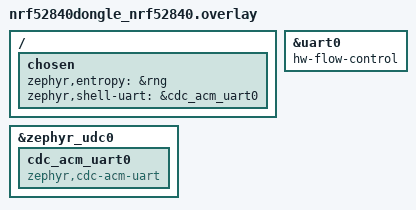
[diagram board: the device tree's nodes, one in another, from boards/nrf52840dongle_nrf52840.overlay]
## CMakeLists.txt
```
#
# Copyright (c) 2022, The OpenThread Authors.
# All rights reserved.
# BDS-3
#

cmake_minimum_required(VERSION 3.20.0)

find_package(Zephyr REQUIRED HINTS $ENV{ZEPHYR_BASE})

project(bbtc)

# NORDIC SDK APP START
target_sources(app PRIVATE src/main.c)
target_sources(app PRIVATE src/otPlatBle.c)
# NORDIC SDK APP END
```

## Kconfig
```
#
# Copyright (c) 2020 Nordic Semiconductor ASA
#
# SPDX-License-Identifier: LicenseRef-Nordic-5-Clause
#

menu "Zephyr Kernel"
source "Kconfig.zephyr"
endmenu

module = BBTC
module-str = bbtc
source "${ZEPHYR_BASE}/subsys/logging/Kconfig.template.log_config"
```

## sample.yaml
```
sample:
  name: BBTC
  description: Test BBTC build
tests:
  sample.openthread.bbtc:
    build_only: true
    platform_allow: nrf5340dk_nrf5340_cpuapp nrf52840dk_nrf52840 nrf52840dongle_nrf52840
    tags: build
    integration_platforms:
      - nrf5340dk_nrf5340_cpuapp
      - nrf52840dk_nrf52840
      - nrf52840dongle_nrf52840
```

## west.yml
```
# Copyright (c) 2023 Nordic Semiconductor ASA
# SPDX-License-Identifier: Apache-2.0

manifest:
  self:
    path: ThreadBleSecure-ncs

  remotes:
    - name: ncs
      url-base: https://github.com/nrfconnect
    - name: canis
      url-base: https://github.com/canisLupus1313

  projects:
    - name: openthread
      remote: canis
      revision: 442f2491efb3a973ef51b56cb48904f2e3eb05df
      path: modules/lib/openthread
    - name: sdk-nrf
      remote: ncs
      revision: v2.3.0
      path: nrf
      import:
        name-blocklist:
          - openthread
          - zephyr
    - name: zephyr
      repo-path: sdk-zephyr
      revision: 9a30ca95bdf405045992ebebe20b5765492bda53
      remote: canis
      import:
        # In addition to the zephyr repository itself, NCS also
        # imports the contents of zephyr/west.yml at the above
        # revision. Only the projects explicitly named in the
        # following allowlist are imported.
        #
        # Note that the zephyr west extensions (like 'build', 'flash',
        # 'debug', etc.) are automatically provided by this import, so
        # there's no need to add a redundant west-commands: key for
        # the zephyr project.
        #
        # Please keep this list sorted alphabetically.
        name-allowlist:
          - TraceRecorderSource
          - canopennode
          - chre
          - cmsis
          - edtt
          - fatfs
          - hal_nordic
          - hal_st # required for ST sensors (unrelated to STM32 MCUs)
          - hal_wurthelektronik
          - liblc3
          - libmetal
          - littlefs
          - loramac-node
          - lvgl
          - lz4
          - mipi-sys-t
          - nanopb
          - net-tools
          - nrf_hw_models
          - open-amp
          - picolibc
          - psa-arch-tests
          - segger
          - tinycbor
          - tinycrypt
          - tf-m-tests
          - uoscore-uedhoc
          - zcbor
          - zscilib
```

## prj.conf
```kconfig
# Copyright (c) 2021 Nordic Semiconductor ASA
# SPDX-License-Identifier: Apache-2.0

# Network shell
CONFIG_SHELL=y
CONFIG_OPENTHREAD_SHELL=y
CONFIG_SHELL_ARGC_MAX=26
CONFIG_SHELL_CMD_BUFF_SIZE=640

# Enable OpenThread features set
CONFIG_OPENTHREAD_NORDIC_LIBRARY_MASTER=y

CONFIG_NET_L2_OPENTHREAD=y

# Enable Ble feture set
CONFIG_OPENTHREAD_BBTC=y
CONFIG_MBEDTLS_GCM_C=y
# Increase MbedTLS heap size from 900 to 2000 for both input and output. Add 2x 1100 to the default value of 10240
CONFIG_MBEDTLS_HEAP_SIZE=12440
CONFIG_MBEDTLS_KEY_EXCHANGE_PSK_ENABLED=y


# Generic networking options
CONFIG_NETWORKING=y

CONFIG_ASSERT=y
CONFIG_ASSERT_NO_COND_INFO=y
CONFIG_MBEDTLS_SHA1_C=n
CONFIG_FPU=y

# Multiprotocol
# -------------
CONFIG_SYSTEM_WORKQUEUE_STACK_SIZE=2144
CONFIG_BT_RX_STACK_SIZE=2048

CONFIG_BT=y
CONFIG_BT_PERIPHERAL=y
CONFIG_BT_DEVICE_NAME="Thread BLE"
CONFIG_BT_DEVICE_APPEARANCE=833

# OpenThread default network config
CONFIG_OPENTHREAD_NETWORKKEY="00:11:22:33:44:55:66:77:88:99:aa:bb:cc:dd:ee:ff"
CONFIG_OPENTHREAD_NETWORK_NAME="OpenThread-7cf7"
CONFIG_OPENTHREAD_XPANID="3b:78:ce:62:9c:bc:8e:23"
CONFIG_OPENTHREAD_PANID=31991
```

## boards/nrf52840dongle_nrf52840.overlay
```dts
/* Copyright (c) 2023 Nordic Semiconductor ASA
 *
 * SPDX-License-Identifier: LicenseRef-Nordic-5-Clause
 */

&uart0 {
	status = "okay";
	hw-flow-control;
};

&zephyr_udc0 {
	cdc_acm_uart0: cdc_acm_uart0 {
		compatible = "zephyr,cdc-acm-uart";
	};
};

/ {
	/*
	* In some default configurations within the nRF Connect SDK,
	* e.g. on nRF52840, the chosen zephyr,entropy node is &cryptocell.
	* This devicetree overlay ensures that default is overridden wherever it
	* is set, as this application uses the RNG node for entropy exclusively.
	*/
	chosen {
		zephyr,entropy = &rng;
		zephyr,shell-uart = &cdc_acm_uart0;
	};
};
```

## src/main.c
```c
/*
 *  Copyright (c) 2022, The OpenThread Authors.
 *  All rights reserved.
 *
 *  Redistribution and use in source and binary forms, with or without
 *  modification, are permitted provided that the following conditions are met:
 *  1. Redistributions of source code must retain the above copyright
 *     notice, this list of conditions and the following disclaimer.
 *  2. Redistributions in binary form must reproduce the above copyright
 *     notice, this list of conditions and the following disclaimer in the
 *     documentation and/or other materials provided with the distribution.
 *  3. Neither the name of the copyright holder nor the
 *     names of its contributors may be used to endorse or promote products
 *     derived from this software without specific prior written permission.
 *
 *  THIS SOFTWARE IS PROVIDED BY THE COPYRIGHT HOLDERS AND CONTRIBUTORS "AS IS"
 *  AND ANY EXPRESS OR IMPLIED WARRANTIES, INCLUDING, BUT NOT LIMITED TO, THE
 *  IMPLIED WARRANTIES OF MERCHANTABILITY AND FITNESS FOR A PARTICULAR PURPOSE
 *  ARE DISCLAIMED. IN NO EVENT SHALL THE COPYRIGHT HOLDER OR CONTRIBUTORS BE
 *  LIABLE FOR ANY DIRECT, INDIRECT, INCIDENTAL, SPECIAL, EXEMPLARY, OR
 *  CONSEQUENTIAL DAMAGES (INCLUDING, BUT NOT LIMITED TO, PROCUREMENT OF
 *  SUBSTITUTE GOODS OR SERVICES; LOSS OF USE, DATA, OR PROFITS; OR BUSINESS
 *  INTERRUPTION) HOWEVER CAUSED AND ON ANY THEORY OF LIABILITY, WHETHER IN
 *  CONTRACT, STRICT LIABILITY, OR TORT (INCLUDING NEGLIGENCE OR OTHERWISE)
 *  ARISING IN ANY WAY OUT OF THE USE OF THIS SOFTWARE, EVEN IF ADVISED OF THE
 *  POSSIBILITY OF SUCH DAMAGE.
 */

#include <zephyr/kernel.h>
#include <zephyr/logging/log.h>

#include <zephyr/drivers/uart.h>
#include <zephyr/usb/usb_device.h>

// Zephyr OpenThread integration Library
#include <zephyr/net/openthread.h>

// OpenThread API
#include <openthread/platform/ble.h>
#include <openthread/ble_secure.h>

#include "x509_cert_key.h"


LOG_MODULE_REGISTER(cli_sample, CONFIG_OT_COMMAND_LINE_INTERFACE_LOG_LEVEL);

struct openthread_context *myOpenThreadContext;
otInstance *myOpenThreadInstance = NULL;  


// BleSecure callback functions

void HandleBleSecureClientConnect(bool aConnected, void *aContext)
{
	LOG_INF("TLS Connected: %s", aConnected ? "YES" : " NO");
}


void HandleBleSecureReceive(otMessage *aMessage, void *aContext)
{
	uint16_t nLen;
	char buf[100];
	
	LOG_INF("TLS Data Received len:%d offset:%d", (int)otMessageGetLength(aMessage), (int)otMessageGetOffset(aMessage));

	//nLen = otMessageGetLength(aMessage) - otMessageGetOffset(aMessage);
    nLen = otMessageRead(aMessage, otMessageGetOffset(aMessage), buf + 5, sizeof(buf) - 6);
	buf[nLen + 5] = 0;

	LOG_INF("Received:%s", buf + 5);
	memcpy(buf, "RECV:", 5);
	otBleSecureSend(myOpenThreadInstance, buf, strlen(buf));
}


// platform -> integrate in OT
void otPlatBleGapOnConnected(otInstance *aInstance, uint16_t aConnectionId)
{
	LOG_INF("OT Connected");
	otBleSecureConnect(myOpenThreadInstance, HandleBleSecureClientConnect, NULL);
}

void otPlatBleGapOnDisconnected(otInstance *aInstance, uint16_t aConnectionId)
{
	LOG_INF("OT Disconnected");
	otBleSecureDisconnect(myOpenThreadInstance);
}


void main(void)
{
#if DT_NODE_HAS_COMPAT(DT_CHOSEN(zephyr_shell_uart), zephyr_cdc_acm_uart)
	int ret;
	const struct device *dev;
	uint32_t dtr = 0U;

	ret = usb_enable(NULL);
	if (ret != 0) {
		LOG_ERR("Failed to enable USB");
		return;
	}

	dev = DEVICE_DT_GET(DT_CHOSEN(zephyr_shell_uart));
	if (dev == NULL) {
		LOG_ERR("Failed to find specific UART device");
		return;
	}

	LOG_INF("Waiting for host to be ready to communicate");

	/* Data Terminal Ready - check if host is ready to communicate */
	while (!dtr) {
		ret = uart_line_ctrl_get(dev, UART_LINE_CTRL_DTR, &dtr);
		if (ret) {
			LOG_ERR("Failed to get Data Terminal Ready line state: %d",
				ret);
			continue;
		}
		k_msleep(100);
	}

	/* Data Carrier Detect Modem - mark connection as established */
	(void)uart_line_ctrl_set(dev, UART_LINE_CTRL_DCD, 1);
	/* Data Set Ready - the NCP SoC is ready to communicate */
	(void)uart_line_ctrl_set(dev, UART_LINE_CTRL_DSR, 1);
#endif

	myOpenThreadContext = openthread_get_default_context();
	myOpenThreadInstance = myOpenThreadContext->instance;

	#if CONFIG_BT
		otBleSecureSetCertificate(myOpenThreadInstance, (const uint8_t*)(OT_CLI_COAPS_X509_CERT),
                               sizeof(OT_CLI_COAPS_X509_CERT), (const uint8_t*)(OT_CLI_COAPS_PRIV_KEY),
                               sizeof(OT_CLI_COAPS_PRIV_KEY));

    	otBleSecureSetCaCertificateChain(myOpenThreadInstance,
                                      (const uint8_t*)(OT_CLI_COAPS_TRUSTED_ROOT_CERTIFICATE),
                                      sizeof(OT_CLI_COAPS_TRUSTED_ROOT_CERTIFICATE));

		otBleSecureSetSslAuthMode(myOpenThreadInstance, true);

		//otBleSecureSetPsk(myOpenThreadInstance, "SECRET", 6, "MyDevice", 8);
		otBleSecureStart(myOpenThreadInstance, HandleBleSecureReceive, false, NULL);
			
	#endif
}
```

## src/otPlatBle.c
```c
/*
 *  Copyright (c) 2022, The OpenThread Authors.
 *  All rights reserved.
 *
 *  Redistribution and use in source and binary forms, with or without
 *  modification, are permitted provided that the following conditions are met:
 *  1. Redistributions of source code must retain the above copyright
 *     notice, this list of conditions and the following disclaimer.
 *  2. Redistributions in binary form must reproduce the above copyright
 *     notice, this list of conditions and the following disclaimer in the
 *     documentation and/or other materials provided with the distribution.
 *  3. Neither the name of the copyright holder nor the
 *     names of its contributors may be used to endorse or promote products
 *     derived from this software without specific prior written permission.
 *
 *  THIS SOFTWARE IS PROVIDED BY THE COPYRIGHT HOLDERS AND CONTRIBUTORS "AS IS"
 *  AND ANY EXPRESS OR IMPLIED WARRANTIES, INCLUDING, BUT NOT LIMITED TO, THE
 *  IMPLIED WARRANTIES OF MERCHANTABILITY AND FITNESS FOR A PARTICULAR PURPOSE
 *  ARE DISCLAIMED. IN NO EVENT SHALL THE COPYRIGHT HOLDER OR CONTRIBUTORS BE
 *  LIABLE FOR ANY DIRECT, INDIRECT, INCIDENTAL, SPECIAL, EXEMPLARY, OR
 *  CONSEQUENTIAL DAMAGES (INCLUDING, BUT NOT LIMITED TO, PROCUREMENT OF
 *  SUBSTITUTE GOODS OR SERVICES; LOSS OF USE, DATA, OR PROFITS; OR BUSINESS
 *  INTERRUPTION) HOWEVER CAUSED AND ON ANY THEORY OF LIABILITY, WHETHER IN
 *  CONTRACT, STRICT LIABILITY, OR TORT (INCLUDING NEGLIGENCE OR OTHERWISE)
 *  ARISING IN ANY WAY OUT OF THE USE OF THIS SOFTWARE, EVEN IF ADVISED OF THE
 *  POSSIBILITY OF SUCH DAMAGE.
 */


// C standard libraries
#include <stddef.h>
#include <string.h>
#include <errno.h>


// Zephir Libraries
#include <zephyr/kernel.h>
#include <zephyr/logging/log.h>
#include <zephyr/types.h>
#include <zephyr/sys/byteorder.h>
#include <soc.h>
#include <zephyr/sys/ring_buffer.h>

#include <zephyr/bluetooth/bluetooth.h>
#include <zephyr/bluetooth/hci.h>
#include <zephyr/bluetooth/conn.h>
#include <zephyr/bluetooth/uuid.h>
#include <zephyr/bluetooth/gatt.h>

// Zephyr OpenThread integration Library
#include <zephyr/net/openthread.h>

// OpenThread BLE driver API
#include <openthread/platform/ble.h>


// --------------
// Zephyr Logging
// --------------

LOG_MODULE_REGISTER(cli_sample_ble_driver, CONFIG_OT_COMMAND_LINE_INTERFACE_LOG_LEVEL);



// ----------------
// Settings
// ----------------

#define DEVICE_NAME 		    CONFIG_BT_DEVICE_NAME
#define DEVICE_NAME_LEN        	(sizeof(DEVICE_NAME) - 1)

// Temporarily use the UUIDs of the Nordic UART service to allow using existing tools for testing
// This will be replaced with a Threadgroup UUID
#define MY_SERVICE_UUID 		BT_UUID_128_ENCODE(0x6e400001, 0xb5a3, 0xf393, 0xe0a9, 0xe50e24dcca9e)
#define RX_CHARACTERISTIC_UUID 	BT_UUID_128_ENCODE(0x6e400002, 0xb5a3, 0xf393, 0xe0a9, 0xe50e24dcca9e)
#define TX_CHARACTERISTIC_UUID  BT_UUID_128_ENCODE(0x6e400003, 0xb5a3, 0xf393, 0xe0a9, 0xe50e24dcca9e)


#define BT_UUID_MY_SERVICE      BT_UUID_DECLARE_128(MY_SERVICE_UUID)
#define BT_UUID_MY_SERVICE_RX   BT_UUID_DECLARE_128(RX_CHARACTERISTIC_UUID)
#define BT_UUID_MY_SERVICE_TX   BT_UUID_DECLARE_128(TX_CHARACTERISTIC_UUID)

#define PLAT_BLE_RING_BUF_SIZE  	500
#define PLAT_BLE_THREAD_STACK_SIZE  6500
#define PLAT_BLE_THREAD_DEALY  		500
#define PLAT_BLE_MSG_DATA_MAX  		23                  // must match the maximum MTU size used

#define PLAT_BLE_MSG_CONNECT  		0xFE
#define PLAT_BLE_MSG_DISCONNECT		0xFF


// ---------------------------------
// Zephyr Kernel Objects
// ---------------------------------

static void otPlatBleThread(void *, void *, void *);
uint8_t otPlatBleMsgBuf[PLAT_BLE_MSG_DATA_MAX];

K_SEM_DEFINE(otPlatBleInitSemaphor, 0, 1);
K_SEM_DEFINE(otPlatBleEventSemaphor, 0, 10000);
RING_BUF_DECLARE(otPlatBleRingBuf, PLAT_BLE_RING_BUF_SIZE);
K_THREAD_DEFINE(otPlatBleTid, PLAT_BLE_THREAD_STACK_SIZE, otPlatBleThread, NULL, NULL, NULL, 5, 0, PLAT_BLE_THREAD_DEALY);


// ---------------------------------
// OpenThread Objects
// ---------------------------------

otInstance *otPlatBleOpenThreadInstance = NULL;


// ---------------------------------
// BLE service Objects
// ---------------------------------

// forward declaration for callback functions
static ssize_t on_receive(struct bt_conn *conn, const struct bt_gatt_attr *attr, const void *buf,  uint16_t len,  uint16_t offset,  uint8_t flags);
void on_cccd_changed(const struct bt_gatt_attr *attr, uint16_t value);

// Service Declaration and Registration
BT_GATT_SERVICE_DEFINE(my_service,
    BT_GATT_PRIMARY_SERVICE(BT_UUID_MY_SERVICE),
    BT_GATT_CHARACTERISTIC(BT_UUID_MY_SERVICE_RX, BT_GATT_CHRC_WRITE | BT_GATT_CHRC_WRITE_WITHOUT_RESP, BT_GATT_PERM_READ | BT_GATT_PERM_WRITE, NULL, on_receive, NULL),
    BT_GATT_CHARACTERISTIC(BT_UUID_MY_SERVICE_TX, BT_GATT_CHRC_NOTIFY, BT_GATT_PERM_READ, NULL, NULL, NULL),
    BT_GATT_CCC(on_cccd_changed, BT_GATT_PERM_READ | BT_GATT_PERM_WRITE),
);



// ---------------------------------
// Zephyr BLE Objects
// ---------------------------------

// forward declaration for callback functions
static void connected(struct bt_conn *conn, uint8_t err);
static void disconnected(struct bt_conn *conn, uint8_t reason);
static bool le_param_req(struct bt_conn *conn, struct bt_le_conn_param *param);
static void le_param_updated(struct bt_conn *conn, uint16_t interval, uint16_t latency, uint16_t timeout);

static struct bt_conn *otPlatBleConnection = NULL;

static struct bt_conn_cb conn_callbacks = {
	.connected		    = connected,
	.disconnected   	= disconnected,
	.le_param_req		= le_param_req,
	.le_param_updated	= le_param_updated
};

static const struct bt_data ad[] =
{
	BT_DATA_BYTES(BT_DATA_FLAGS, (BT_LE_AD_GENERAL | BT_LE_AD_NO_BREDR)), BT_DATA(BT_DATA_NAME_COMPLETE, DEVICE_NAME, DEVICE_NAME_LEN),
};

static const struct bt_data sd[] =
{
	BT_DATA_BYTES(BT_DATA_UUID128_ALL, MY_SERVICE_UUID),
};



// ------------------------------------------------------------------
// Zephyr BLE Message Queue and Thread
// ------------------------------------------------------------------

// SDK integration: Should be includeded in the OpenThread Thread to avoid the need for another Thread with large stack

static bool otPlatBleQueueMsg(const uint8_t* aData, uint8_t aLen, int8_t aRssi)
{
	bool bRetVal;

	if(aLen <= PLAT_BLE_MSG_DATA_MAX && aData == NULL) return false;

	k_sched_lock();

	if(ring_buf_space_get(&otPlatBleRingBuf) >= sizeof(aLen) + sizeof(aRssi) + (aLen <= PLAT_BLE_MSG_DATA_MAX) ? aLen : 0)
    {
		ring_buf_put(&otPlatBleRingBuf, &aLen, sizeof(aLen));
		ring_buf_put(&otPlatBleRingBuf, &aRssi, sizeof(aRssi));
		if(aLen <= PLAT_BLE_MSG_DATA_MAX) ring_buf_put(&otPlatBleRingBuf, aData, aLen);
		k_sem_give(&otPlatBleEventSemaphor);
		bRetVal = true;
	}
	else bRetVal = false;

	k_sched_unlock();

	return bRetVal;
}


static void otPlatBleThread(void *a, void *b, void *c)
{
	OT_UNUSED_VARIABLE(a);
	OT_UNUSED_VARIABLE(b);
	OT_UNUSED_VARIABLE(c);

	uint8_t len;
	int8_t rssi;
	otBleRadioPacket myPacket;

	LOG_INF("otPlatBleThread started");

	while(1)
    {
        k_sem_take(&otPlatBleEventSemaphor, K_FOREVER);
        ring_buf_get(&otPlatBleRingBuf, &len, sizeof(len));
		ring_buf_get(&otPlatBleRingBuf, &rssi, sizeof(rssi));
        if(len <= PLAT_BLE_MSG_DATA_MAX) ring_buf_get(&otPlatBleRingBuf, otPlatBleMsgBuf, len);

		openthread_api_mutex_lock(openthread_get_default_context());

		if(len <= PLAT_BLE_MSG_DATA_MAX)
		{
			// The packet parameter in otPlatBleGattServerOnWriteRequest is not const. Re-write all members.
			myPacket.mValue = otPlatBleMsgBuf;
			myPacket.mPower = rssi;
			myPacket.mLength = len;
			otPlatBleGattServerOnWriteRequest(otPlatBleOpenThreadInstance, 0, &myPacket);
		}
		else if(len == PLAT_BLE_MSG_CONNECT) otPlatBleGapOnConnected(otPlatBleOpenThreadInstance, 0);
		else if(len == PLAT_BLE_MSG_DISCONNECT) otPlatBleGapOnDisconnected(otPlatBleOpenThreadInstance, 0);

		openthread_api_mutex_unlock(openthread_get_default_context());
	}
}


// ------------------------------------------------------------------
// Zephyr BLE service callbacks
// ------------------------------------------------------------------

/* This function is called whenever the RX Characteristic has been written to by a Client */
static ssize_t on_receive(struct bt_conn *conn, const struct bt_gatt_attr *attr, const void *buf,  uint16_t len,  uint16_t offset,  uint8_t flags)
{
	LOG_INF("Received data, handle %d, len %d", attr->handle, len);

	otPlatBleQueueMsg(buf, len, 0 /* TBD */);

	return len;
}


/* This function is called whenever a Notification has been sent by the TX Characteristic */
static void on_sent(struct bt_conn *conn, void *user_data)
{
	ARG_UNUSED(user_data);

	// LOG_INF("Data sent\n");
}


/* This function is called whenever the CCCD register has been changed by the client*/
void on_cccd_changed(const struct bt_gatt_attr *attr, uint16_t value)
{
    ARG_UNUSED(attr);
    switch(value)
    {
        case BT_GATT_CCC_NOTIFY:
			// How should the device driver inform about CCCD change?
			// Quick fix: Delay otPlatBleGapOnConnected(...) until notifications can be sent.
		    otPlatBleQueueMsg(NULL, PLAT_BLE_MSG_CONNECT, 0);
            break;

        case BT_GATT_CCC_INDICATE:
            break;

        case 0:
            break;
    }
}


otError otPlatBleGattServerIndicate(otInstance *aInstance, uint16_t aHandle, otBleRadioPacket *aPacket)
{
	OT_UNUSED_VARIABLE(aInstance);

    const struct bt_gatt_attr *attr = &my_service.attrs[3];

    struct bt_gatt_notify_params params =
    {
        .uuid   = BT_UUID_MY_SERVICE_TX,
        .attr   = attr,
        .data   = aPacket->mValue,
        .len    = aPacket->mLength,
        .func   = on_sent
    };

	// Only one connection supported
	if(aHandle != 0) return OT_ERROR_INVALID_ARGS;

	if(otPlatBleConnection == NULL) return OT_ERROR_INVALID_STATE;

    // Check whether notifications are enabled or not
    if(bt_gatt_is_subscribed(otPlatBleConnection, attr, BT_GATT_CCC_NOTIFY))
    {
        // Send the notification
	    if(bt_gatt_notify_cb(otPlatBleConnection, &params))
        {
            LOG_INF("Error, unable to send notification\n");
			return OT_ERROR_INVALID_ARGS;
        }
    }
    else
    {
        LOG_INF("Warning, notification not enabled on the selected attribute\n");
		return OT_ERROR_INVALID_STATE;
    }

	return OT_ERROR_NONE;
}


otError otPlatBleGattMtuGet(otInstance *aInstance, uint16_t *aMtu)
{
	OT_UNUSED_VARIABLE(aInstance);

	if(otPlatBleConnection == NULL) return OT_ERROR_FAILED;

	if(aMtu != NULL) *aMtu = bt_gatt_get_mtu(otPlatBleConnection);

	return OT_ERROR_NONE;
}


otError otPlatBleGapDisconnect(otInstance *aInstance)
{
	OT_UNUSED_VARIABLE(aInstance);

	if(otPlatBleConnection == NULL) return OT_ERROR_INVALID_STATE;

	if(bt_conn_disconnect(otPlatBleConnection, BT_HCI_ERR_REMOTE_USER_TERM_CONN))
	{
		return OT_ERROR_INVALID_STATE;
	}

	return OT_ERROR_NONE;
}

// ------------------------------------------------------------------
// Zephyr BLE callbacks
// ------------------------------------------------------------------

static void connected(struct bt_conn *conn, uint8_t err)
{
	struct bt_conn_info info;
	char addr[BT_ADDR_LE_STR_LEN];

	otPlatBleConnection = bt_conn_ref(conn);

	if(err)
	{
		LOG_INF("Connection failed (err %u)\n", err);
		return;
	}
	else if(bt_conn_get_info(conn, &info))
	{
		LOG_INF("Could not parse connection info\n");
	}
	else
	{
		bt_addr_le_to_str(bt_conn_get_dst(conn), addr, sizeof(addr));

		LOG_INF("Connection established!\n");
	}
}


static void disconnected(struct bt_conn *conn, uint8_t reason)
{
	LOG_INF("Disconnected (reason %u)\n", reason);

	if(otPlatBleConnection)
	{
		bt_conn_unref(otPlatBleConnection);
		otPlatBleConnection = NULL;

		otPlatBleQueueMsg(NULL, PLAT_BLE_MSG_DISCONNECT, 0);
	}
}


static bool le_param_req(struct bt_conn *conn, struct bt_le_conn_param *param)
{
	return true;
}


static void le_param_updated(struct bt_conn *conn, uint16_t interval, uint16_t latency, uint16_t timeout)
{
	struct bt_conn_info info;
	char addr[BT_ADDR_LE_STR_LEN];

	if(bt_conn_get_info(conn, &info))
	{
		LOG_INF("Could not parse connection info\n");
	}
	else
	{
		bt_addr_le_to_str(bt_conn_get_dst(conn), addr, sizeof(addr));

		LOG_INF("Connection parameters updated!\n");
	}
}


static void bt_ready(int err)
{
	if(err)
    {
		LOG_INF("BLE init failed with error code %d\n", err);
		return;
	}

	bt_conn_cb_register(&conn_callbacks);

    k_sem_give(&otPlatBleInitSemaphor);   // BLE stack up an running
}


otError otPlatBleGapAdvStart(otInstance *aInstance, uint16_t aInterval, uint8_t aType)
{
	OT_UNUSED_VARIABLE(aInstance);
	OT_UNUSED_VARIABLE(aInterval);			// To be decided how to derive the min max range from this value
	OT_UNUSED_VARIABLE(aType);				// Not need. Must be connectable for BLE secure.

	int err;

	err = bt_le_adv_start(BT_LE_ADV_CONN, ad, ARRAY_SIZE(ad), sd, ARRAY_SIZE(sd));

	if(err)
	{
		LOG_INF("Advertising failed to start (err %d)\n", err);
		return OT_ERROR_INVALID_STATE;
	}

	LOG_INF("Advertising successfully started\n");

	return OT_ERROR_NONE;
}


otError otPlatBleGapAdvStop(otInstance *aInstance)
{
	OT_UNUSED_VARIABLE(aInstance);

	bt_le_adv_stop();

	return OT_ERROR_NONE;
}



// ------------------------------------------------------------------
// Zephyr BLE initialization
// ------------------------------------------------------------------

otError otPlatBleEnable(otInstance *aInstance)
{
    int err;

	otPlatBleOpenThreadInstance = aInstance;
    err = bt_enable(bt_ready);

    if(err)
    {
		LOG_INF("BLE enable failed with error code %d\n", err);
		return OT_ERROR_FAILED;
	}

    err = k_sem_take(&otPlatBleInitSemaphor, K_MSEC(500));

	if (!err)
	{
		LOG_INF("Bluetooth initialized\n");
	}
	else
	{
		LOG_INF("BLE initialization did not complete in time\n");
		return OT_ERROR_FAILED;
	}

	return OT_ERROR_NONE;
}

otError otPlatBleDisable(otInstance *aInstance)
{
	OT_UNUSED_VARIABLE(aInstance);

	bt_disable();

	return OT_ERROR_NONE;
}
```

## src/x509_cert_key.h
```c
/*
 *  Copyright (c) 2022, The OpenThread Authors.
 *  All rights reserved.
 *
 *  Redistribution and use in source and binary forms, with or without
 *  modification, are permitted provided that the following conditions are met:
 *  1. Redistributions of source code must retain the above copyright
 *     notice, this list of conditions and the following disclaimer.
 *  2. Redistributions in binary form must reproduce the above copyright
 *     notice, this list of conditions and the following disclaimer in the
 *     documentation and/or other materials provided with the distribution.
 *  3. Neither the name of the copyright holder nor the
 *     names of its contributors may be used to endorse or promote products
 *     derived from this software without specific prior written permission.
 *
 *  THIS SOFTWARE IS PROVIDED BY THE COPYRIGHT HOLDERS AND CONTRIBUTORS "AS IS"
 *  AND ANY EXPRESS OR IMPLIED WARRANTIES, INCLUDING, BUT NOT LIMITED TO, THE
 *  IMPLIED WARRANTIES OF MERCHANTABILITY AND FITNESS FOR A PARTICULAR PURPOSE
 *  ARE DISCLAIMED. IN NO EVENT SHALL THE COPYRIGHT HOLDER OR CONTRIBUTORS BE
 *  LIABLE FOR ANY DIRECT, INDIRECT, INCIDENTAL, SPECIAL, EXEMPLARY, OR
 *  CONSEQUENTIAL DAMAGES (INCLUDING, BUT NOT LIMITED TO, PROCUREMENT OF
 *  SUBSTITUTE GOODS OR SERVICES; LOSS OF USE, DATA, OR PROFITS; OR BUSINESS
 *  INTERRUPTION) HOWEVER CAUSED AND ON ANY THEORY OF LIABILITY, WHETHER IN
 *  CONTRACT, STRICT LIABILITY, OR TORT (INCLUDING NEGLIGENCE OR OTHERWISE)
 *  ARISING IN ANY WAY OUT OF THE USE OF THIS SOFTWARE, EVEN IF ADVISED OF THE
 *  POSSIBILITY OF SUCH DAMAGE.
 */

/**
 * @file
 * @brief
 *  This file contains the X.509 certificate and private key for Application
 *  CoAP Secure use with cipher suite ECDHE_ECDSA_WITH_AES_128_CCM8.
 */


/**SERVER
 * Generate your own private key and certificate using openssl.
 *
 * 1. Generate a EC (Elliptic Curve) Private Key.
 *      'openssl ecparam -genkey -out myECKey.pem -name prime256v1 -noout'
 * 2. Generate a .X509 Certificate (Contains Public Key).
 *      'openssl req -x509 -new -key myECKey.pem -out myX509Cert.pem'
 */

/**
 * place your X.509 certificate (PEM format) for ssl session
 * with ECDHE_ECDSA_WITH_AES_128_CCM_8 here.
 */
#define OT_CLI_COAPS_X509_CERT                                             \
    "-----BEGIN CERTIFICATE-----\r\n"                                      \
    "MIIBrTCCAVICBgDRArfDJTAKBggqhkjOPQQDAjBcMQswCQYDVQQGEwJaWTESMBAG\r\n" \
    "A1UECAwJWW91clN0YXRlMRAwDgYDVQQKDAdZb3VyT3JnMRQwEgYDVQQLDAtZb3Vy\r\n" \
    "T3JnVW5pdDERMA8GA1UEAwwIVmVuZG9yQ0EwIBcNMTgwNzEzMTIzNzA3WhgPMjI5\r\n" \
    "MjA0MjYxMjM3MDdaMGExCzAJBgNVBAYTAlpZMRIwEAYDVQQIDAlZb3VyU3RhdGUx\r\n" \
    "EDAOBgNVBAoMB1lvdXJPcmcxFDASBgNVBAsMC1lvdXJPcmdVbml0MRYwFAYDVQQD\r\n" \
    "DA1QWEMzLkU3NS0xMDBBMFkwEwYHKoZIzj0CAQYIKoZIzj0DAQcDQgAEIUtlV99w\r\n" \
    "OggiASflg6CVsGMzXMXYrNgQ1piLIybCkrq+YoqJ3mwcbJHWlvxGPxNIQw6i8kzK\r\n" \
    "bkC642ZWgBT5MzAKBggqhkjOPQQDAgNJADBGAiEA/1yk69A+37kLBvdOWPDRXGwe\r\n" \
    "0AoICTGaLqzB3cF5mtACIQC28WwmzHb5gqe3nOPAM73py1v17EXZj07PU89BAEcb\r\n" \
    "yg==\r\n"                                                             \
    "-----END CERTIFICATE-----\r\n"

/**
 * place your private key (PEM format) for ssl session
 * with ECDHE_ECDSA_WITH_AES_128_CCM_8 here.
 */
#define OT_CLI_COAPS_PRIV_KEY                                              \
    "-----BEGIN EC PRIVATE KEY-----\r\n"                                   \
    "MHcCAQEEIFYQh2R7M48qOHePw+VE4b034UlZmWWC/iNAK34sQbucoAoGCCqGSM49\r\n" \
    "AwEHoUQDQgAEIUtlV99wOggiASflg6CVsGMzXMXYrNgQ1piLIybCkrq+YoqJ3mwc\r\n" \
    "bJHWlvxGPxNIQw6i8kzKbkC642ZWgBT5Mw==\r\n"                             \
    "-----END EC PRIVATE KEY-----\r\n"

/**
 * Place peers CA certificate (PEM format) here.
 * It's necessary to validate the peers certificate. If you haven't a
 * CA certificate, you must run the coaps without checking certificate.
 */
#define OT_CLI_COAPS_TRUSTED_ROOT_CERTIFICATE                              \
    "-----BEGIN CERTIFICATE-----\r\n"                                      \
    "MIICDzCCAbWgAwIBAgIESZYC0jAKBggqhkjOPQQDAjBcMQswCQYDVQQGEwJaWTES\r\n" \
    "MBAGA1UECAwJWW91clN0YXRlMRAwDgYDVQQKDAdZb3VyT3JnMRQwEgYDVQQLDAtZ\r\n" \
    "b3VyT3JnVW5pdDERMA8GA1UEAwwIVmVuZG9yQ0EwIBcNMTgwNzEzMTE1NjA5WhgP\r\n" \
    "MjI5MjA0MjYxMTU2MDlaMFwxCzAJBgNVBAYTAlpZMRIwEAYDVQQIDAlZb3VyU3Rh\r\n" \
    "dGUxEDAOBgNVBAoMB1lvdXJPcmcxFDASBgNVBAsMC1lvdXJPcmdVbml0MREwDwYD\r\n" \
    "VQQDDAhWZW5kb3JDQTBZMBMGByqGSM49AgEGCCqGSM49AwEHA0IABGAAuYcBIgP0\r\n" \
    "fMC1Bd+1nAH5S1goR0TaDAIadK4hULQr5LwziuDk9XTQaOTwmWB9iR1eiHC6RY8W\r\n" \
    "wyrGBbnEbzujYzBhMB0GA1UdDgQWBBQ+yCpIszhzbmXe2At1GofREjnBxjAfBgNV\r\n" \
    "HSMEGDAWgBQ+yCpIszhzbmXe2At1GofREjnBxjAPBgNVHRMBAf8EBTADAQH/MA4G\r\n" \
    "A1UdDwEB/wQEAwIBhjAKBggqhkjOPQQDAgNIADBFAiBW60XgdSRD24rbTgdneS+V\r\n" \
    "SHVix8LuXunPYW50LmxbrwIhAOw4gMroRIOS26y0TcND03FnyO3wBNF9MjM0hWKQ\r\n" \
    "JXk3\r\n"                                                             \
    "-----END CERTIFICATE-----\r\n"
```
